# N32WB03X register map
Vendor: Nationstech Ltd.; File version: 1.0
Registers are 32-bit, read-write, reset 0x0 unless marked. A register's access mark holds for its fields unless they carry their own. Offsets are from the block's base; lines under a group give offsets from that group; [hi:lo] are bit positions; {n}, {i} and the like mark numbered series; 'fields as' and 'values as' point back to an identical list; <NAME> marks a mode.

## Memory map
0x40000400 TIM3 size 0x400 — General purpose timer
0x40001000 TIM6 size 0x400 — Basic timer
0x40002800 RTC size 0x400 — Real time clock
0x40002C00 WWDG size 0x400 — window watchdog
0x40003000 IWDG size 0x400 — Independent watchdog
0x40004400 USART2 size 0x400
0x40004800 LPUART1 size 0x400 — Low-power universal asynchronous receiver transmitter
0x40005400 I2C1 size 0x400 — Inter integrated circuit
0x40007000 PWR size 0x400 — Power control
0x40010000 AFIO size 0x400 — Alternate function I/O
0x40010400 EXTI size 0x400 — external interrupt/event controller
0x40010800 GPIOA size 0x400 — General purpose I/O
0x40010C00 GPIOB size 0x400
0x40011400 KYESCAN size 0x200 — KEYSCAN unit
0x40012000 SPI1 size 0x400 — Serial peripheral interface
0x40012C00 TIM1 size 0x400 — Advanced timer
0x40013800 USART1 size 0x400 — Universal synchronous asynchronous receiver transmitter
0x40014400 SPI2 size 0x400
0x40020000 DMA size 0x400 — Direct memory access controller
0x40020800 ADC size 0x400 — analog to digital converter
0x40021000 RCC size 0x400 — Reset and clock control
0x40023000 CRC size 0x400 — cyclic redundancy check

## Interrupts
0 WWDG — WWDG interrupt
2 RTC — RTC global interrupt
5 RCC — RCC interrupt
6 EXTI0_1 (EXTI) — EXTI0/1 interrupt
7 EXTI2_3 (EXTI) — EXTI2/3 interrupt
8 EXTI4_12 (EXTI) — EXTI4/5/6/7/8/9/10/11/12 interrupt
11 DMA_Channel1_2_3_4 (DMA) — DMA channel1 channel2 channel3 channel4 interrupt
12 DMA_Channel5 (DMA) — DMA channel5 interrupt
13 TIM1_BRK (TIM1) — TIM1 Break/Update/Trigger/Commutation interrupt
14 TIM1_CC (TIM1) — TIM1 Capture Compare interrupt
16 TIM3 — TIM3 global interrupt
21 ADC — ADC global interrupt
22 SPI2 — SPI2 global interrupt
23 I2C1 — I2C1 global interrupt
25 SPI1 — SPI1 global interrupt
27 KEYSCAN (KYESCAN) — KEYSCAN global interrupt
28 USART1 — USART1 global interrupt
29 LPUART1 — LPUART1 global interrupt
30 USART2 — USART2 global interrupt

## ADC — analog to digital converter
Base 0x40020800
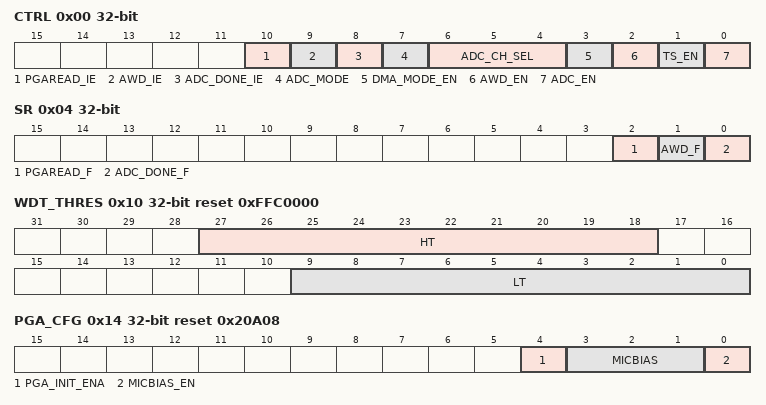
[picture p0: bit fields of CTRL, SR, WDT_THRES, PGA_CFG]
0x00 CTRL (reset mask 0x3FF)
  [10] PGAREAD_IE, [9] AWD_IE, [8] ADC_DONE_IE, [7] ADC_MODE, [6:4] ADC_CH_SEL, [3] DMA_MODE_EN, [2] AWD_EN, [1] TS_EN, [0] ADC_EN
0x04 SR
  [2] PGAREAD_F, [1] AWD_F, [0] ADC_DONE_F
0x08 OVR_SAMP_CNT reset 0x1F
  [3:0] OS_CNT_LD_CNT
0x0C DAT
  [15:0] ADC_DATA
0x10 WDT_THRES reset 0xFFC0000
  [27:18] HT, [9:0] LT
0x14 PGA_CFG reset 0x20A08
  [4] PGA_INIT_ENA
  [3:1] MICBIAS — SAMP1
  [0] MICBIAS_EN
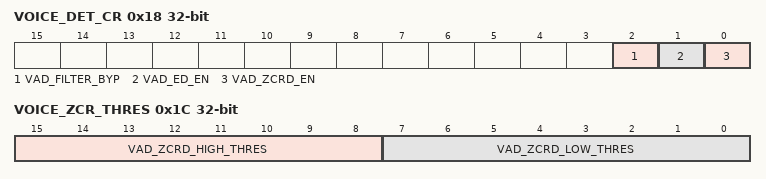
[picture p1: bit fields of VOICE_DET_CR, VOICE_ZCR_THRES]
0x18 VOICE_DET_CR (reset mask 0x3)
  [2] VAD_FILTER_BYP, [1] VAD_ED_EN, [0] VAD_ZCRD_EN
0x1C VOICE_ZCR_THRES
  [15:8] VAD_ZCRD_HIGH_THRES
  [7:0] VAD_ZCRD_LOW_THRES — VAD_ZCRD_HIGH_THRES
0x20 VOICE_ED_THRES
  [22:0] MOFFSET
0x24 VOICE_ED_DWN_THRES
  [22:0] GATE_MIN
0x28 VOICE_ED_UP_THRES
  [22:0] GATE_MAX

## KYESCAN — KEYSCAN unit
Base 0x40011400
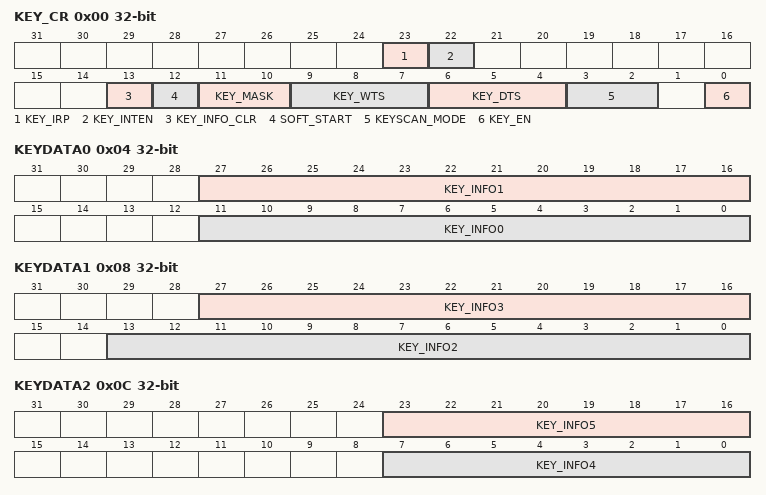
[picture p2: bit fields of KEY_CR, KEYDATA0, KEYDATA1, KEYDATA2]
0x00 KEY_CR
  [23] KEY_IRP, [22] KEY_INTEN, [13] KEY_INFO_CLR, [12] SOFT_START, [11:10] KEY_MASK, [9:7] KEY_WTS, [6:4] KEY_DTS, [3:2] KEYSCAN_MODE, [0] KEY_EN
0x04 KEYDATA0
  [27:16] KEY_INFO1, [11:0] KEY_INFO0
0x08 KEYDATA1
  [27:16] KEY_INFO3, [13:0] KEY_INFO2
0x0C KEYDATA2
  [23:16] KEY_INFO5, [7:0] KEY_INFO4
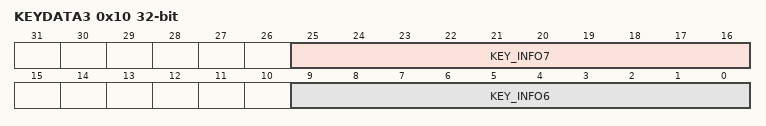
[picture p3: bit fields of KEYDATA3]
0x10 KEYDATA3
  [25:16] KEY_INFO7, [9:0] KEY_INFO6
0x14 KEYDATA4
  [11:0] KEY_INFO8

## CRC — cyclic redundancy check
Base 0x40023000
0x00 CRC32DAT reset 0xFFFFFFFF
0x04 CRC32IDAT
  [7:0] CRC32IDAT
0x08 CRC32CTRL
  [0] RESET
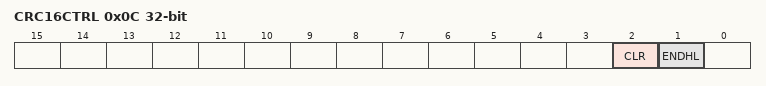
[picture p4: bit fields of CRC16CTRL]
0x0C CRC16CTRL
  [2] CLR, [1] ENDHL
0x10 CRC16DAT
  [7:0] CRC16DAT
0x14 CRC16D
  [15:0] CRC16D
0x18 LRC
  [7:0] LRCDAT

## DMA — Direct memory access controller
Base 0x40020000
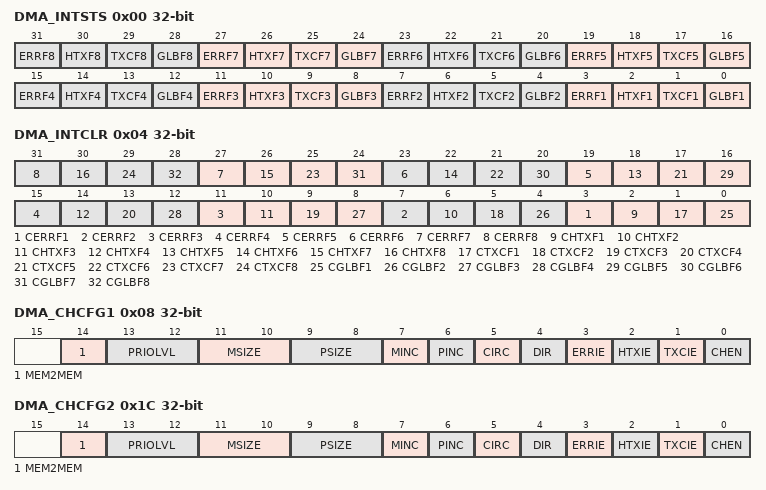
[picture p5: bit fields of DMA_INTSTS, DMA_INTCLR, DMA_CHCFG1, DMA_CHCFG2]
0x00 DMA_INTSTS
  [4n-1] ERRF{n} (n=1..8), [4n-2] HTXF{n} (n=1..8), [4n-3] TXCF{n} (n=1..8), [4n-4] GLBF{n} (n=1..8)
0x04 DMA_INTCLR
  [4n-1] CERRF{n} (n=1..8), [4n-2] CHTXF{n} (n=1..8), [4n-3] CTXCF{n} (n=1..8), [4n-4] CGLBF{n} (n=1..8)
0x08 DMA_CHCFG1
  [14] MEM2MEM, [13:12] PRIOLVL, [11:10] MSIZE, [9:8] PSIZE, [7] MINC, [6] PINC, [5] CIRC, [4] DIR, [3] ERRIE, [2] HTXIE, [1] TXCIE, [0] CHEN
0x0C DMA_TXNUM1
  [15:0] NDTX
0x10 DMA_PADDR1
  [31:0] ADDR
{0x0+0x14*i} DMA_MADDR{i} (i=1..5)
  [31:0] ADDR
{0x4+0x14*i} DMA_CHSEL{i} (i=1..5)
  [5:0] CH_SEL
0x1C DMA_CHCFG2
  fields as DMA_CHCFG1
0x20 DMA_TXNUM2
  [15:0] NDTX
0x24 DMA_PADDR2
  [31:0] ADDR
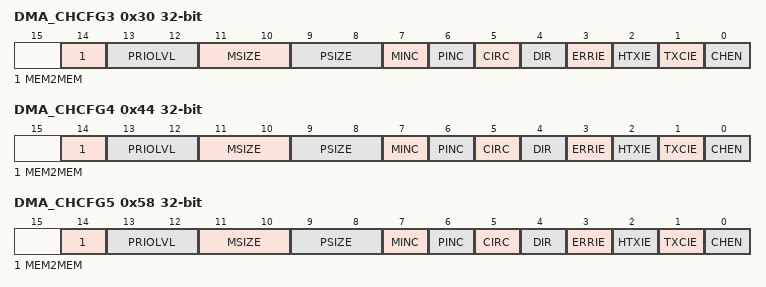
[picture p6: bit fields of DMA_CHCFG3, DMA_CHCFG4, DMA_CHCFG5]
0x30 DMA_CHCFG3
  fields as DMA_CHCFG1
0x34 DMA_TXNUM3
  [15:0] NDTX
0x38 DMA_PADDR3
  [31:0] ADDR
0x44 DMA_CHCFG4
  fields as DMA_CHCFG1
0x48 DMA_TXNUM4
  [15:0] NDTX
0x4C DMA_PADDR4
  [31:0] ADDR
0x58 DMA_CHCFG5
  fields as DMA_CHCFG1
0x5C DMA_TXNUM5
  [15:0] NDTX
0x60 DMA_PADDR5
  [31:0] ADDR
